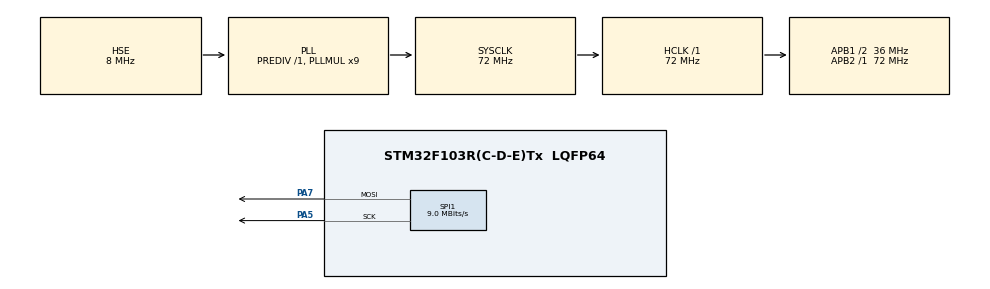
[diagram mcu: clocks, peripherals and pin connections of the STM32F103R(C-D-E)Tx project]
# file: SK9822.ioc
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Mcu.Family=STM32F1
Mcu.Name=STM32F103R(C-D-E)Tx
Mcu.Package=LQFP64
NVIC.PriorityGroup=NVIC_PRIORITYGROUP_4
PA13.Mode=Serial_Wire
PA13.Signal=SYS_JTMS-SWDIO
PA14.Mode=Serial_Wire
PA14.Signal=SYS_JTCK-SWCLK
PA5.Mode=TX_Only_Simplex_Unidirect_Master
PA5.Signal=SPI1_SCK
PA7.Mode=TX_Only_Simplex_Unidirect_Master
PA7.Signal=SPI1_MOSI
PD0-OSC_IN.Mode=HSE-External-Oscillator
PD0-OSC_IN.Signal=RCC_OSC_IN
PD1-OSC_OUT.Mode=HSE-External-Oscillator
PD1-OSC_OUT.Signal=RCC_OSC_OUT
ProjectManager.HeapSize=0x200
ProjectManager.StackSize=0x400
ProjectManager.TargetToolchain=STM32CubeIDE
RCC.AHBFreq_Value=72000000
RCC.APB1CLKDivider=RCC_HCLK_DIV2
RCC.APB1Freq_Value=36000000
RCC.APB1TimFreq_Value=72000000
RCC.APB2Freq_Value=72000000
RCC.APB2TimFreq_Value=72000000
RCC.HCLKFreq_Value=72000000
RCC.PLLMUL=RCC_PLL_MUL9
RCC.PLLSourceVirtual=RCC_PLLSOURCE_HSE
RCC.SYSCLKFreq_VALUE=72000000
RCC.SYSCLKSource=RCC_SYSCLKSOURCE_PLLCLK
RCC.USBFreq_Value=72000000
SPI1.BaudRatePrescaler=SPI_BAUDRATEPRESCALER_8
SPI1.CLKPhase=SPI_PHASE_2EDGE
SPI1.CLKPolarity=SPI_POLARITY_HIGH
SPI1.CalculateBaudRate=9.0 MBits/s
SPI1.Direction=SPI_DIRECTION_2LINES
SPI1.Mode=SPI_MODE_MASTER
SPI1.VirtualType=VM_MASTER
board=custom

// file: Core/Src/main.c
/* USER CODE BEGIN Header */
/**
  ******************************************************************************
  * @file           : main.c
  * @brief          : Main program body
  ******************************************************************************
  * @attention
  *
  * Copyright (c) 2023 STMicroelectronics.
  * All rights reserved.
  *
  * This software is licensed under terms that can be found in the LICENSE file
  * in the root directory of this software component.
  * If no LICENSE file comes with this software, it is provided AS-IS.
  *
  ******************************************************************************
  */
/* USER CODE END Header */
#include "main.h"
#include "spi.h"
#include "gpio.h"

void SystemClock_Config(void);

/* USER CODE BEGIN 0 */

#define LED_COUNT 12  // 定义LED的数量
/*LED全局变量*/
uint8_t led_data[12][4]={0x1f,0x00,0x00,0x00,	//led阵列设置：亮度(最大0x1f)，蓝，绿，红
                    0x1f,0x00,0x00,0x00,
                    0x1f,0x00,0x00,0x00,
                    0x1f,0x00,0x00,0x00,
                    0x1f,0x00,0x00,0x00,
                    0x1f,0x00,0x00,0x00,
                    0x1f,0x00,0x00,0x00,
                    0x1f,0x00,0x00,0x00,
                    0x1f,0x00,0x00,0x00,
                    0x1f,0x00,0x00,0x00,
                    0x1f,0x00,0x00,0x00,
                    0x1f,0x00,0x00,0x00};
void SK9822_SendByte(uint8_t data)
{
    HAL_SPI_Transmit(&hspi1, &data, 1, HAL_MAX_DELAY);
}
void SK9822_StartFrame(void)
{
    uint8_t startFrame[4] = {0x00, 0x00, 0x00, 0x00};
    HAL_SPI_Transmit(&hspi1, startFrame, sizeof(startFrame), HAL_MAX_DELAY);
}
void SK9822_EndFrame(void)
{
    uint8_t endFrame[4] = {0xFF, 0xFF, 0xFF, 0xFF};
    HAL_SPI_Transmit(&hspi1, endFrame, sizeof(endFrame), HAL_MAX_DELAY);
}

void SK9822_SetLEDColor(uint8_t *led_data)
{
    SK9822_SendByte((*led_data)|0xE0);
    SK9822_SendByte(*(led_data+1));
    SK9822_SendByte(*(led_data+2));
    SK9822_SendByte(*(led_data+3));
}
void SK9822_clear(uint8_t led_num)
{
    uint8_t i,led_clear[4]={0,0,0,0};
    SK9822_StartFrame();
    for(i=0;i<led_num;i++)
    {
        SK9822_SetLEDColor(led_clear);
    }
    SK9822_EndFrame();
}
void SK9822_disp(uint8_t led_num,uint8_t led_data[][4])
{
    uint8_t i;
    SK9822_StartFrame();
    for(i=0;i<led_num;i++)
    {
        SK9822_SetLEDColor(*(led_data+i));
    }
    SK9822_EndFrame();
}
void controlLEDPattern(uint8_t ledIndex, uint8_t red, uint8_t green, uint8_t blue) {
    led_data[ledIndex][3] = red;    // 设置红色分量
    led_data[ledIndex][2] = green;  // 设置绿色分量
    led_data[ledIndex][1] = blue;   // 设置蓝色分量

    SK9822_disp(LED_COUNT, led_data);  // 更新LED显示
}

/* USER CODE END 0 */

int main(void)
{

  /* MCU Configuration--------------------------------------------------------*/

  /* Reset of all peripherals, Initializes the Flash interface and the Systick. */
  HAL_Init();

  /* Configure the system clock */
  SystemClock_Config();

  /* Initialize all configured peripherals */
  MX_GPIO_Init();
  MX_SPI1_Init();

  /* Infinite loop */
    while (1) {
        for (int i = 0; i < 12; i++) {
            controlLEDPattern(i, 255/i, 8*i, 3*i);
            HAL_Delay(500);
        }
        controlLEDPattern(13, 25, 25, 30);
    }
}

void SystemClock_Config(void)
{
  RCC_OscInitTypeDef RCC_OscInitStruct = {0};
  RCC_ClkInitTypeDef RCC_ClkInitStruct = {0};

  /** Initializes the RCC Oscillators according to the specified parameters
  * in the RCC_OscInitTypeDef structure.
  */
  RCC_OscInitStruct.OscillatorType = RCC_OSCILLATORTYPE_HSE;
  RCC_OscInitStruct.HSEState = RCC_HSE_ON;
  RCC_OscInitStruct.HSEPredivValue = RCC_HSE_PREDIV_DIV1;
  RCC_OscInitStruct.HSIState = RCC_HSI_ON;
  RCC_OscInitStruct.PLL.PLLState = RCC_PLL_ON;
  RCC_OscInitStruct.PLL.PLLSource = RCC_PLLSOURCE_HSE;
  RCC_OscInitStruct.PLL.PLLMUL = RCC_PLL_MUL9;
  if (HAL_RCC_OscConfig(&RCC_OscInitStruct) != HAL_OK)
  {
    Error_Handler();
  }

  /** Initializes the CPU, AHB and APB buses clocks
  */
  RCC_ClkInitStruct.ClockType = RCC_CLOCKTYPE_HCLK|RCC_CLOCKTYPE_SYSCLK
                              |RCC_CLOCKTYPE_PCLK1|RCC_CLOCKTYPE_PCLK2;
  RCC_ClkInitStruct.SYSCLKSource = RCC_SYSCLKSOURCE_PLLCLK;
  RCC_ClkInitStruct.AHBCLKDivider = RCC_SYSCLK_DIV1;
  RCC_ClkInitStruct.APB1CLKDivider = RCC_HCLK_DIV2;
  RCC_ClkInitStruct.APB2CLKDivider = RCC_HCLK_DIV1;

  if (HAL_RCC_ClockConfig(&RCC_ClkInitStruct, FLASH_LATENCY_2) != HAL_OK)
  {
    Error_Handler();
  }
}

void Error_Handler(void)
{
    __disable_irq();
    while (1) {
    }
}
